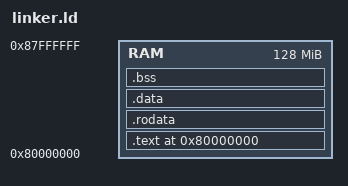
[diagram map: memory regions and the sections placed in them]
ENTRY(_start)

MEMORY
{
    RAM : ORIGIN = 0x80000000, LENGTH = 128M
}

SECTIONS
{
    . = 0x80000000;

    .text : {
        *(.text.boot)
        *(.text*)
    } > RAM

    .rodata : {
        *(.rodata*)
    } > RAM

    .data : {
        *(.data*)
    } > RAM

    .bss : {
        __bss_start = .;
        *(.bss*)
        *(COMMON)
        __bss_end = .;
    } > RAM

    . = ALIGN(16);
    __stack_top = . + 0x4000;      /* 16 KB Hyp stack */
}
